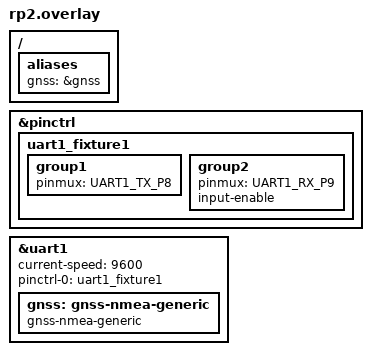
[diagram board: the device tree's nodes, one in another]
/* SPDX-License-Identifier: Apache-2.0 OR MIT */

/ {
	aliases {
		gnss = &gnss;
	};
};

&pinctrl {
	uart1_fixture1: uart1_fixture1 {
		group1 {
			pinmux = <UART1_TX_P8>;
		};
		group2 {
			pinmux = <UART1_RX_P9>;
			input-enable;
		};
	};
};

/*
 * The receiver as a plain NMEA source: Zephyr's generic NMEA driver on
 * UART1 (GP8 TX, GP9 RX, served on the harness by the PIO UART) at the
 * part's power-up rate. The driver sends nothing; it reads GGA and RMC.
 */
&uart1 {
	status = "okay";
	current-speed = <9600>;
	pinctrl-0 = <&uart1_fixture1>;
	pinctrl-names = "default";

	gnss: gnss-nmea-generic {
		compatible = "gnss-nmea-generic";
		status = "okay";
	};
};
